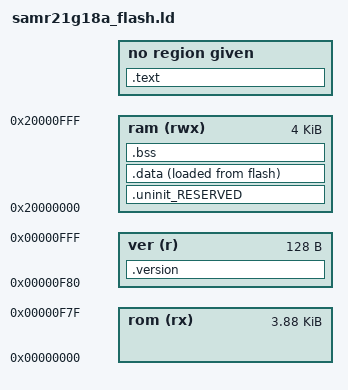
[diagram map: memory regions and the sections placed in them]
/**
 * \file
 *
 * \brief Linker script for running in internal FLASH on the SAMR21G18A
 *
 * Copyright (c) 2016 Atmel Corporation,
 *                    a wholly owned subsidiary of Microchip Technology Inc.
 *
 * \asf_license_start
 *
 * \page License
 *
 * Licensed under the Apache License, Version 2.0 (the "License");
 * you may not use this file except in compliance with the License.
 * You may obtain a copy of the Licence at
 *
 *     http://www.apache.org/licenses/LICENSE-2.0
 *
 * Unless required by applicable law or agreed to in writing, software
 * distributed under the License is distributed on an "AS IS" BASIS,
 * WITHOUT WARRANTIES OR CONDITIONS OF ANY KIND, either express or implied.
 * See the License for the specific language governing permissions and
 * limitations under the License.
 *
 * \asf_license_stop
 *
 */


OUTPUT_FORMAT("elf32-littlearm", "elf32-littlearm", "elf32-littlearm")
OUTPUT_ARCH(arm)
SEARCH_DIR(.)

/* Memory Spaces Definitions */
MEMORY
{
  rom    (rx)  : ORIGIN = 0x00000000, LENGTH = 0x00000F80
  ver    (r)   : ORIGIN = 0x00000F80, LENGTH = 0x00000080
  ram    (rwx) : ORIGIN = 0x20000000, LENGTH = 0x00001000
}

__top_flash = ORIGIN(flash) + LENGTH(flash);
__top_ram = ORIGIN(ram) + LENGTH(ram);

ENTRY(Reset_Handler)

SECTIONS
{
  .version :
  {
      . = ALIGN(4);
      KEEP(*(.version))
  } > ver

  .text : ALIGN(4)
  {
    FILL(0xff)
    KEEP(*(.vectors))
    *(.text*)
    *(.rodata)
    *(.rodata.*)
    . = ALIGN(4);
  } > flash

  . = ALIGN(4);
  __data_load_start__ = .;

  .uninit_RESERVED : ALIGN(4)
  {
    KEEP(*(.bss.$RESERVED*))
  } > ram

  .data : ALIGN(4)
  {
    FILL(0xff)
    __data_start__ = .;
    *(.ramfunc .ramfunc.*);
    *(vtable)
    *(.data*)
    . = ALIGN(4);
    __data_end__ = .;
  } > ram AT > flash

  .bss : ALIGN(4)
  {
    __bss_start__ = .;
    *(.bss*)
    *(COMMON)
    . = ALIGN(4);
    __bss_end__ = .;
    PROVIDE(_end = .);
  } > ram

  PROVIDE(__stack_end__ = __top_ram - 0);
}
